# HT32F1654 register map
Vendor: Holtek Semiconductor; Series: HT32F1xxx; File version: 1.0
This is the description for the Holtek HT32F1654
CPU: CM3 r2p0, little endian, VTOR, 4 interrupt priority bits, 69 interrupts
Registers are 32-bit, read-write, reset 0x0 unless marked. A register's access mark holds for its fields unless they carry their own. Offsets are from the block's base; lines under a group give offsets from that group; [hi:lo] are bit positions; {n}, {i} and the like mark numbered series; 'fields as' and 'values as' point back to an identical list; <NAME> marks a mode.

## Memory map
0xE000E000 NVIC size 0x1000 — Nested Vectored Interrupt Controller
0xE000E010 SysTick size 0x1000
0xE000ED00 SCB size 0x1000
0xE000ED28 Fault_Reports size 0x1000

## Interrupts
15 SysTick

## NVIC — Nested Vectored Interrupt Controller
Base 0xE000E000
0x04 ICTR — Interrupt Controller Type Register
  [4:0] INTLINESNUM
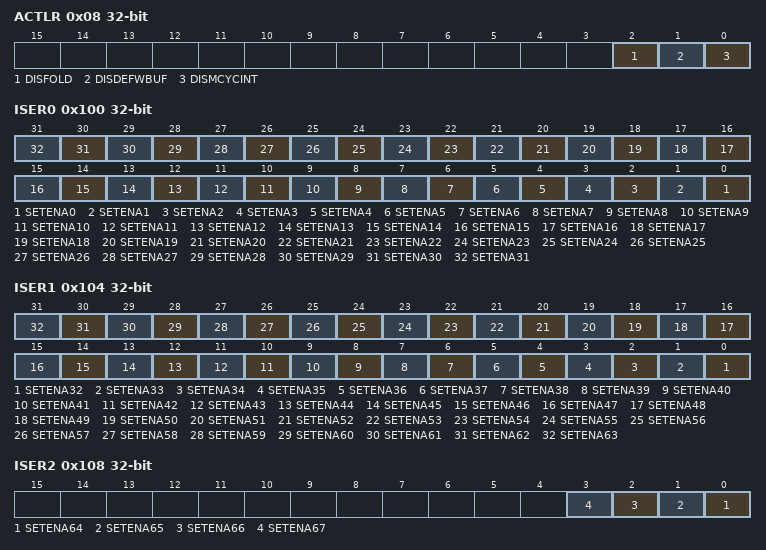
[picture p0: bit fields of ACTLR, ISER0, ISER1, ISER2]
0x08 ACTLR — Auxiliary Control Register
  [2] DISFOLD, [1] DISDEFWBUF, [0] DISMCYCINT
0x100 ISER0 — Interrupt Set-Enable Register 0
  [n] SETENA{n} (n=0..31)
0x104 ISER1 — Interrupt Set-Enable Register 1
  [n-32] SETENA{n} (n=32..63)
0x108 ISER2 — Interrupt Set-Enable Register 2
  [n-64] SETENA{n} (n=64..67)
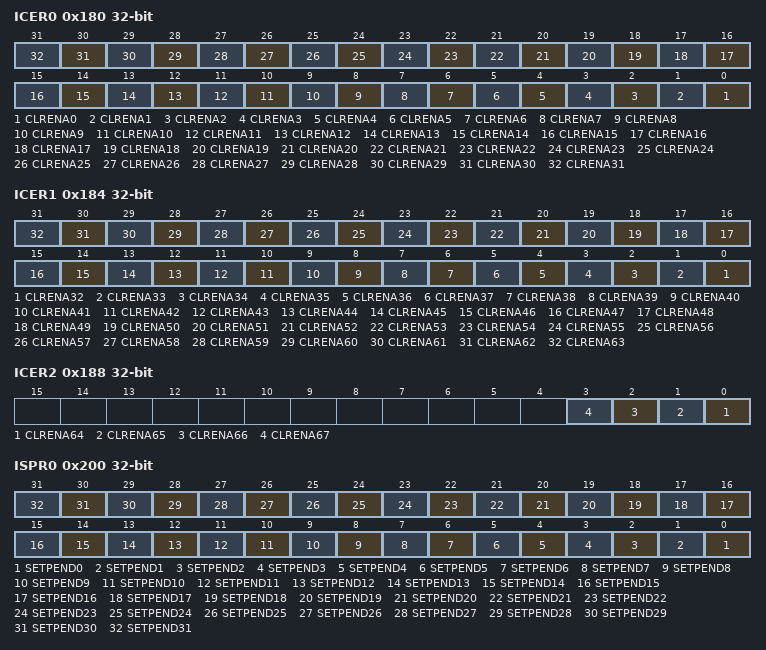
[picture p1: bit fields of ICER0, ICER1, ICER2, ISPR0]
0x180 ICER0 — Interrupt Clear-Enable Register 0
  [n] CLRENA{n} (n=0..31)
0x184 ICER1 — Interrupt Clear-Enable Register 1
  [n-32] CLRENA{n} (n=32..63)
0x188 ICER2 — Interrupt Clear-Enable Register 2
  [n-64] CLRENA{n} (n=64..67)
0x200 ISPR0 — Interrupt Set-Pending Register 0
  [n] SETPEND{n} (n=0..31)
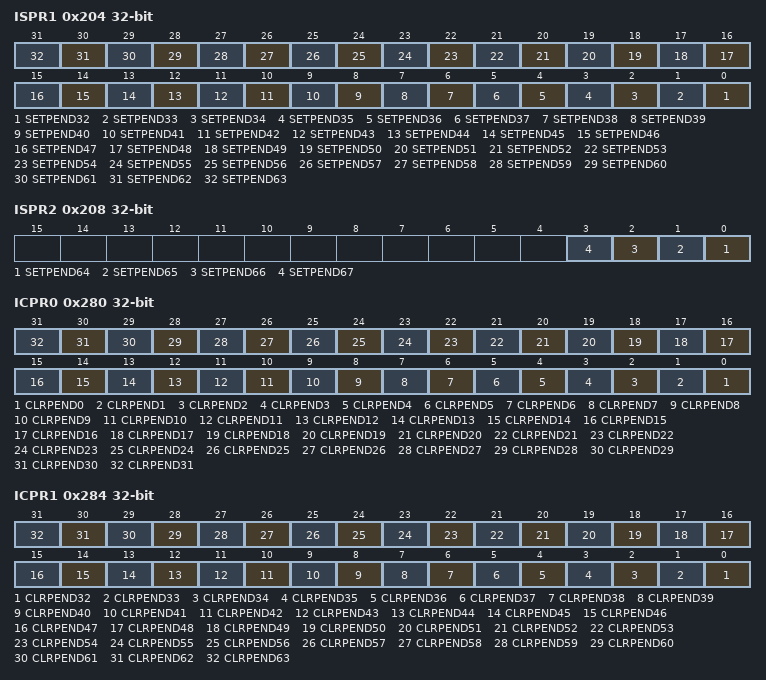
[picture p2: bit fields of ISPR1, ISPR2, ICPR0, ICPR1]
0x204 ISPR1 — Interrupt Set-Pending Register 1
  [n-32] SETPEND{n} (n=32..63)
0x208 ISPR2 — Interrupt Set-Pending Register 2
  [n-64] SETPEND{n} (n=64..67)
0x280 ICPR0 — Interrupt Clear-Pending Register 0
  [n] CLRPEND{n} (n=0..31)
0x284 ICPR1 — Interrupt Clear-Pending Register 1
  [n-32] CLRPEND{n} (n=32..63)
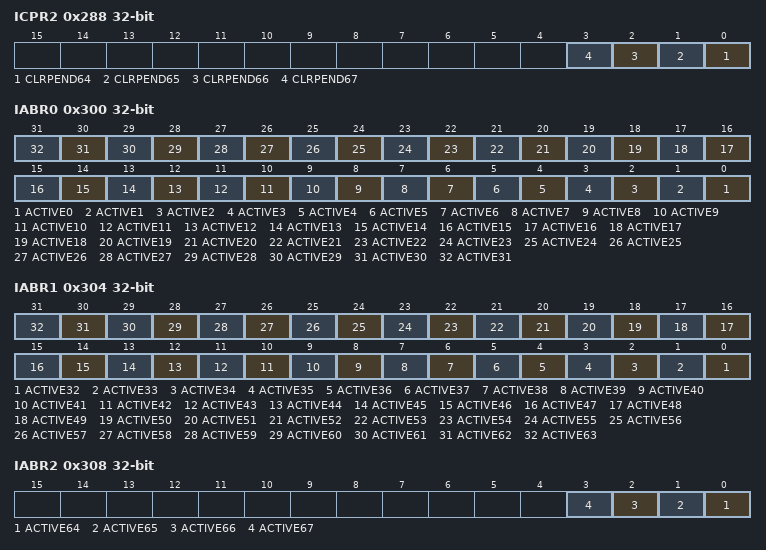
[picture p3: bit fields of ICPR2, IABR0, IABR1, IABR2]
0x288 ICPR2 — Interrupt Clear-Pending Register 2
  [n-64] CLRPEND{n} (n=64..67)
0x300 IABR0 — Interrupt Active Bit Register 0
  [n] ACTIVE{n} (n=0..31)
0x304 IABR1 — Interrupt Active Bit Register 1
  [n-32] ACTIVE{n} (n=32..63)
0x308 IABR2 — Interrupt Active Bit Register 2
  [n-64] ACTIVE{n} (n=64..67)
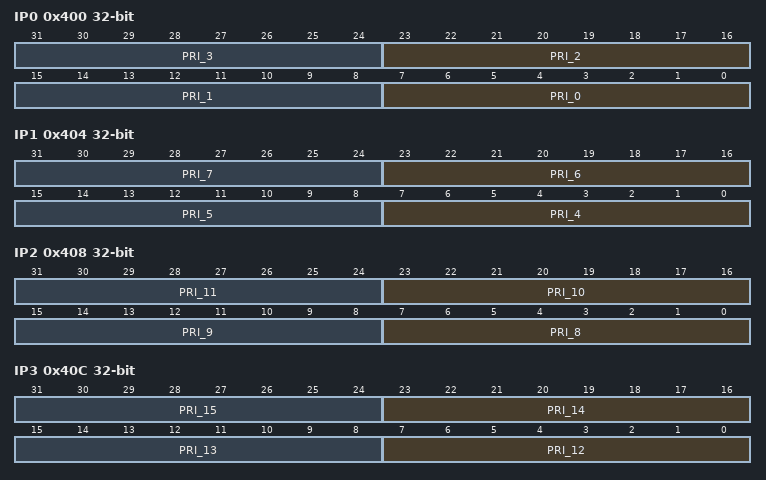
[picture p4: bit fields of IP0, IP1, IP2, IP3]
0x400 IP0 — Interrupt Priority Register 0
  [8n+7:8n] PRI_{n} (n=0..3)
0x404 IP1 — Interrupt Priority Register 1
  [8n-25:8n-32] PRI_{n} (n=4..7)
0x408 IP2 — Interrupt Priority Register 2
  [8n-57:8n-64] PRI_{n} (n=8..11)
0x40C IP3 — Interrupt Priority Register 3
  [8n-89:8n-96] PRI_{n} (n=12..15)
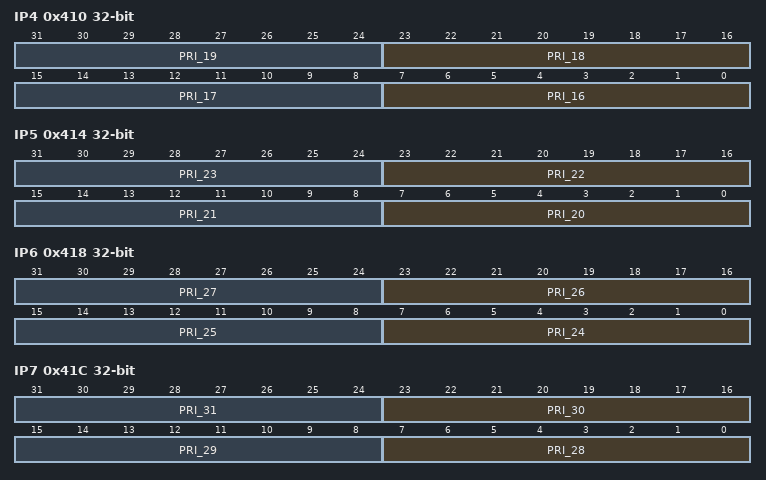
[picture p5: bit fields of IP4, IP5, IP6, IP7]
0x410 IP4 — Interrupt Priority Register 4
  [8n-121:8n-128] PRI_{n} (n=16..19)
0x414 IP5 — Interrupt Priority Register 5
  [8n-153:8n-160] PRI_{n} (n=20..23)
0x418 IP6 — Interrupt Priority Register 6
  [8n-185:8n-192] PRI_{n} (n=24..27)
0x41C IP7 — Interrupt Priority Register 7
  [8n-217:8n-224] PRI_{n} (n=28..31)
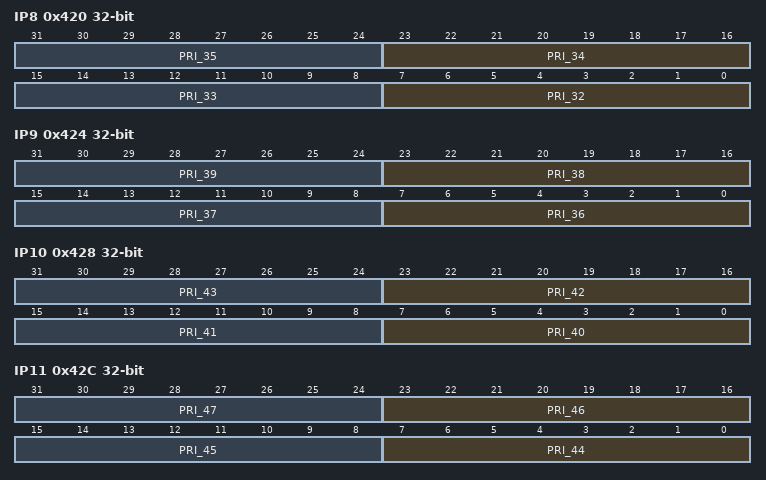
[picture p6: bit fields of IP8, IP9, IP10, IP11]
0x420 IP8 — Interrupt Priority Register 8
  [8n-249:8n-256] PRI_{n} (n=32..35)
0x424 IP9 — Interrupt Priority Register 9
  [8n-281:8n-288] PRI_{n} (n=36..39)
0x428 IP10 — Interrupt Priority Register 10
  [8n-313:8n-320] PRI_{n} (n=40..43)
0x42C IP11 — Interrupt Priority Register 11
  [8n-345:8n-352] PRI_{n} (n=44..47)
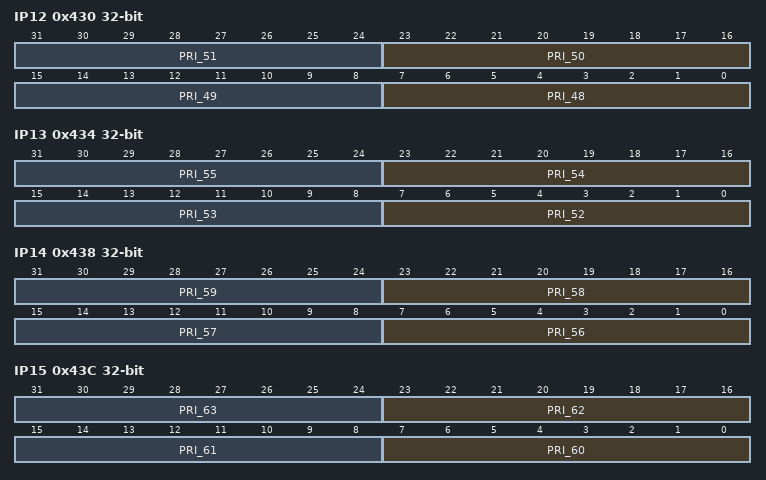
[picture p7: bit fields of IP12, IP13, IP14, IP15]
0x430 IP12 — Interrupt Priority Register 12
  [8n-377:8n-384] PRI_{n} (n=48..51)
0x434 IP13 — Interrupt Priority Register 13
  [8n-409:8n-416] PRI_{n} (n=52..55)
0x438 IP14 — Interrupt Priority Register 14
  [8n-441:8n-448] PRI_{n} (n=56..59)
0x43C IP15 — Interrupt Priority Register 15
  [8n-473:8n-480] PRI_{n} (n=60..63)
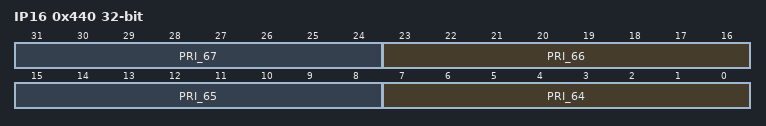
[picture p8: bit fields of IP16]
0x440 IP16 — Interrupt Priority Register 16
  [8n-505:8n-512] PRI_{n} (n=64..67)
0xF00 STIR — Software Trigger Interrupt Register
  [8:0] INTID

## SCB
Base 0xE000ED00
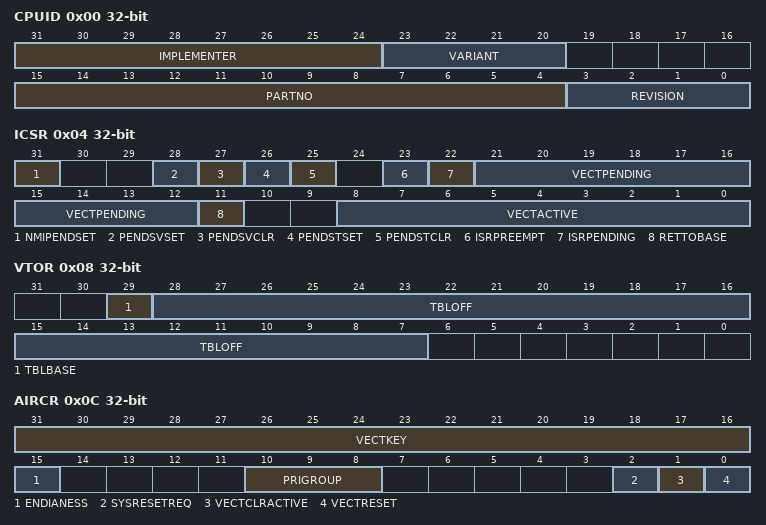
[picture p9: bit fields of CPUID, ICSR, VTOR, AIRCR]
0x00 CPUID
  [31:24] IMPLEMENTER, [23:20] VARIANT, [15:4] PARTNO, [3:0] REVISION
0x04 ICSR — Interrupt Control and State Register
  [31] NMIPENDSET, [28] PENDSVSET, [27] PENDSVCLR, [26] PENDSTSET, [25] PENDSTCLR, [23] ISRPREEMPT, [22] ISRPENDING, [21:12] VECTPENDING, [11] RETTOBASE, [8:0] VECTACTIVE
0x08 VTOR — Vector Table Offset Register
  [29] TBLBASE, [28:7] TBLOFF
0x0C AIRCR — Application Interrupt and Reset Control Register
  [31:16] VECTKEY, [15] ENDIANESS, [10:8] PRIGROUP, [2] SYSRESETREQ, [1] VECTCLRACTIVE, [0] VECTRESET
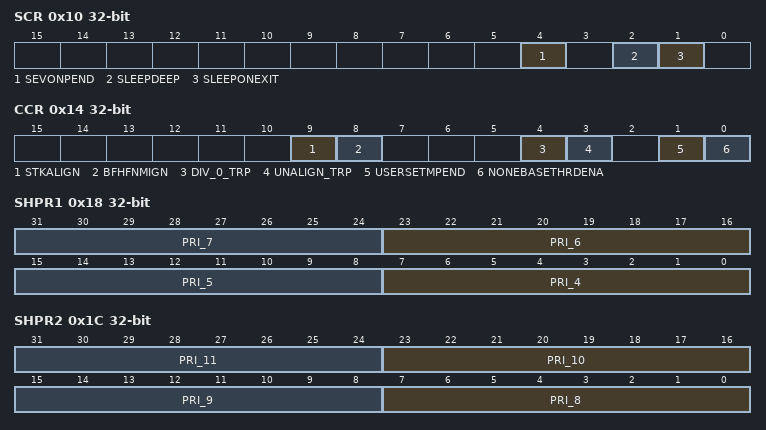
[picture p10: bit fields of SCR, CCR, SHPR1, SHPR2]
0x10 SCR
  [4] SEVONPEND, [2] SLEEPDEEP, [1] SLEEPONEXIT
0x14 CCR
  [9] STKALIGN, [8] BFHFNMIGN, [4] DIV_0_TRP, [3] UNALIGN_TRP, [1] USERSETMPEND, [0] NONEBASETHRDENA
0x18 SHPR1 — System Handler Priority Register 1
  [8n-25:8n-32] PRI_{n} (n=4..7)
0x1C SHPR2 — System Handler Priority Register 2
  [8n-57:8n-64] PRI_{n} (n=8..11)
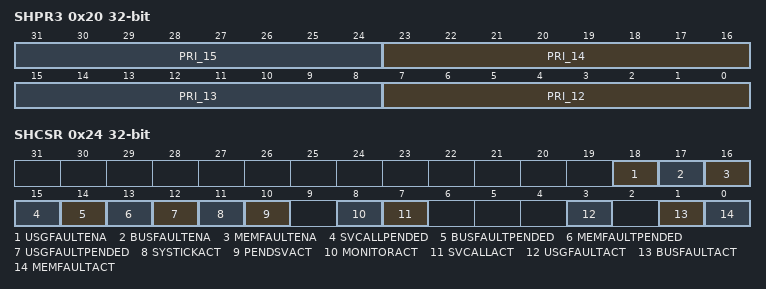
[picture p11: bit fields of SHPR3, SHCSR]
0x20 SHPR3 — System Handler Priority Register 3
  [8n-89:8n-96] PRI_{n} (n=12..15)
0x24 SHCSR
  [18] USGFAULTENA, [17] BUSFAULTENA, [16] MEMFAULTENA, [15] SVCALLPENDED, [14] BUSFAULTPENDED, [13] MEMFAULTPENDED, [12] USGFAULTPENDED, [11] SYSTICKACT, [10] PENDSVACT, [8] MONITORACT, [7] SVCALLACT, [3] USGFAULTACT, [1] BUSFAULTACT, [0] MEMFAULTACT

## SysTick
Base 0xE000E010
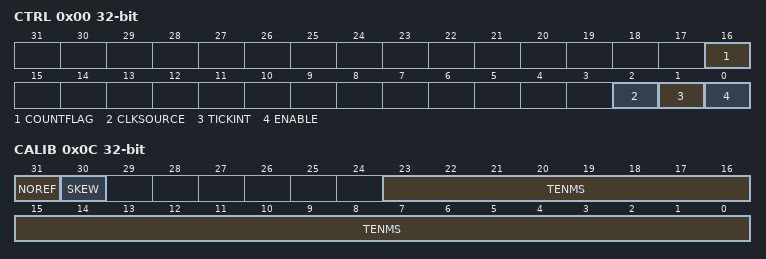
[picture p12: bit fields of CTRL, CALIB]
0x00 CTRL
  [16] COUNTFLAG, [2] CLKSOURCE, [1] TICKINT, [0] ENABLE
0x04 LOAD
  [23:0] RELOAD
0x08 VAL
  [23:0] CURRENT
0x0C CALIB
  [31] NOREF, [30] SKEW, [23:0] TENMS

## Fault_Reports
Base 0xE000ED28
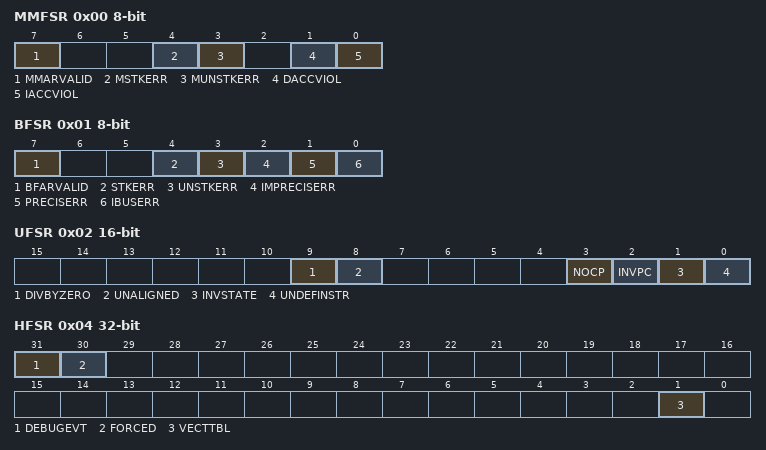
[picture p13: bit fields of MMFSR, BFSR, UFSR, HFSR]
0x00 MMFSR 8-bit — MemManage Status Register
  [7] MMARVALID, [4] MSTKERR, [3] MUNSTKERR, [1] DACCVIOL, [0] IACCVIOL
0x01 BFSR 8-bit — BusFault Status Register
  [7] BFARVALID, [4] STKERR, [3] UNSTKERR, [2] IMPRECISERR, [1] PRECISERR, [0] IBUSERR
0x02 UFSR 16-bit — UsageFault Status Register
  [9] DIVBYZERO, [8] UNALIGNED, [3] NOCP, [2] INVPC, [1] INVSTATE, [0] UNDEFINSTR
0x04 HFSR — HardFault Status Register
  [31] DEBUGEVT, [30] FORCED, [1] VECTTBL
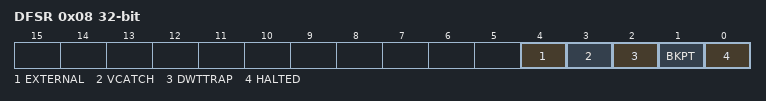
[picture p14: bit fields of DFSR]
0x08 DFSR — Debug Fault Status Register
  [4] EXTERNAL, [3] VCATCH, [2] DWTTRAP, [1] BKPT, [0] HALTED
0x0C MMFAR — MemManage Fault Address Register
  [31:0] ADDRESS
0x10 BFAR — BusFault Address Register
  [31:0] ADDRESS
0x14 AFSR — Auxiliary Fault Status Register
  [31:0] IMPDEF

## Notices in the file
Copyright (C) 2010 ARM Limited. All rights reserved.
ARM Limited (ARM) is supplying this SVD description for use with Cortex-M3
processor based microcontrollers.  This file and or content can be freely
distributed within development tools that are supporting such ARM based
processors.
THIS SOFTWARE IS PROVIDED "AS IS".  NO WARRANTIES, WHETHER EXPRESS, IMPLIED
OR STATUTORY, INCLUDING, BUT NOT LIMITED TO, IMPLIED WARRANTIES OF
MERCHANTABILITY AND FITNESS FOR A PARTICULAR PURPOSE APPLY TO THIS SOFTWARE.
ARM SHALL NOT, IN ANY CIRCUMSTANCES, BE LIABLE FOR SPECIAL, INCIDENTAL, OR
CONSEQUENTIAL DAMAGES, FOR ANY REASON WHATSOEVER.
